# NANO100BN_v1 register map
File version: 1.0
Registers are 32-bit, read-write, reset 0x0 unless marked. A register's access mark holds for its fields unless they carry their own. Offsets are from the block's base; [hi:lo] are bit positions; {n}, {i} and the like mark numbered series; 'fields as' and 'values as' point back to an identical list.

## DAC — DAC Register Map
Base 0x400A0000
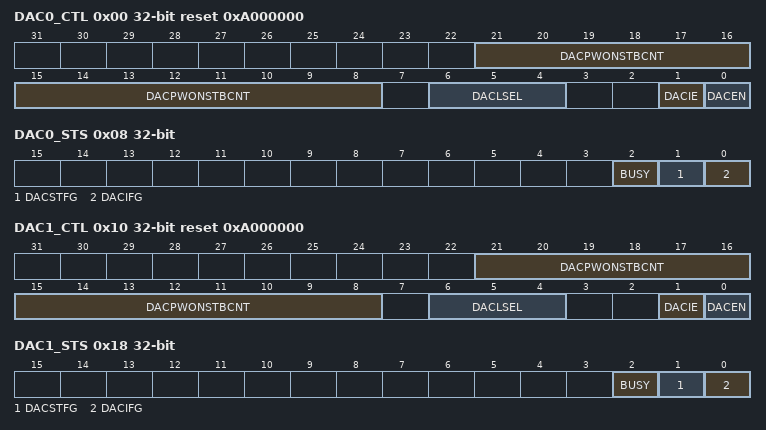
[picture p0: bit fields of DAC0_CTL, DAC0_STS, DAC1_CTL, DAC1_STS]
0x00 DAC0_CTL reset 0xA000000 — DAC0 Control Register
  [21:8] DACPWONSTBCNT — DACPWONSTBCNT. DAC need 6 us to be stable after DAC is power on from power down state. This fied controls a internal counter (in PCLK unit) to guarantee DAC stable time requirement.
  [6:4] DACLSEL — DAC Load Selection
  [1] DACIE — DAC Interrupt Enable
    0=Disabled; 1=Enabled
  [0] DACEN — DAC Enable. Note: When DAC is powered on, DAC will automatically start conversion after waiting for DACPWONSTBCNT+1 PCLK cycle.
    0=Power down DAC; 1=Power on DAC
0x04 DAC0_DATA
  [11:0] DACData
0x08 DAC0_STS — DAC0 Status Register
  [2] BUSY — BUSY bit
    0=DAC is not busy; 1=DAC is busy
  [1] DACSTFG — DAC start flag. Note: this bit is read only.
    0=DAC is not start yet; 1=DAC has been started
  [0] DACIFG — DAC Interrupt flag. Note: This bit is read only.
    0=No interrupt pending; 1=Interrupt pending
0x10 DAC1_CTL reset 0xA000000 — DAC1 Control Register
  fields as DAC0_CTL
0x14 DAC1_DATA
  [11:0] DACData
0x18 DAC1_STS — DAC1 Status Register
  fields as DAC0_STS
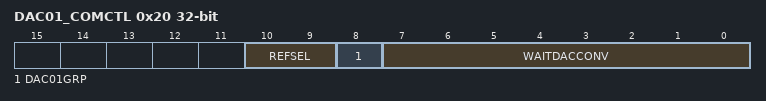
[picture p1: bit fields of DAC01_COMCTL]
0x20 DAC01_COMCTL — DAC01 Common Control Register
  [10:9] REFSEL — Reference Voltage Selection
  [8] DAC01GRP — Group DAC0 and DAC1.
    0=Not grouped; 1=Grouped
  [7:0] WAITDACCONV — Wait DAC Conversion Complete. The DAC needs at least 2 us to settle down every time when each data deliver to DAC, which means user cannot update each DACx_data register faster than 2 us; otherwise data will lost. Setting this register can adjust the time interval in PCLK unit between each DACx_data into DAC in order to meet the 2 us requirement.

## DMA_GCR — DMA Register Map
Base 0x50008F00
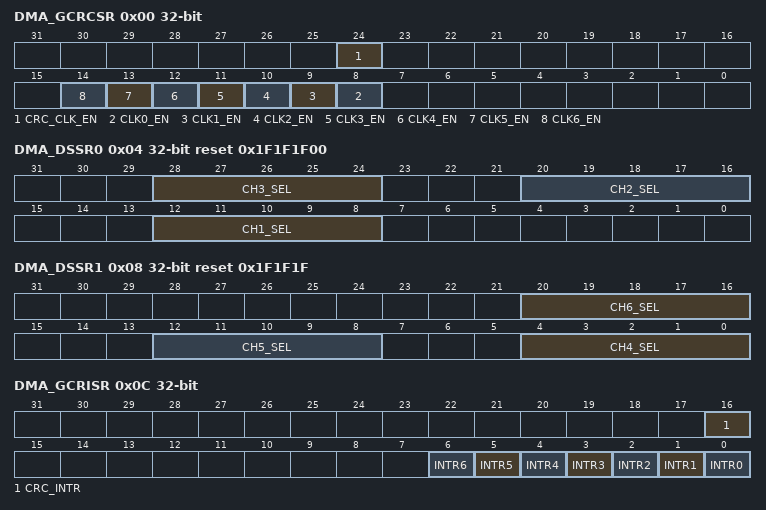
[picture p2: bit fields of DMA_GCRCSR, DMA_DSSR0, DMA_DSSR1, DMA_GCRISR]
0x00 DMA_GCRCSR — DMA Global Control and Status Register
  [all] fields
    0=Disabled; 1=Enabled
  [24] CRC_CLK_EN — CRC Controller Clock Enable Control
  [n+8] CLK{n}_EN (n=0..6) — DMA Controller Channel {n} Clock Enable Control
0x04 DMA_DSSR0 reset 0x1F1F1F00 — DMA Service Selection Control Register 0
  [28:24] CH3_SEL — Channel 3 Selection. This filed defines which peripheral is connected to PDMA channel 3. Software can configure the peripheral setting by CH3_SEL. The channel configuration is the same as CH1_SEL field. Please refer to the explanation of CH1_SEL.
  [20:16] CH2_SEL — Channel 2 Selection. This filed defines which peripheral is connected to PDMA channel 2. Software can configure the peripheral setting by CH2_SEL. The channel configuration is the same as CH1_SEL field. Please refer to the explanation of CH1_SEL.
  [12:8] CH1_SEL — Channel 1 Selection
0x08 DMA_DSSR1 reset 0x1F1F1F — DMA Service Selection Control Register 1
  [20:16] CH6_SEL — Channel 6 Selection. This filed defines which peripheral is connected to PDMA channel 6. Software can configure the peripheral setting by CH6_SEL. The channel configuration is the same as CH4_SEL field. Please refer to the explanation of CH4_SEL.
  [12:8] CH5_SEL — Channel 5 Selection. This filed defines which peripheral is connected to PDMA channel 5. Software can configure the peripheral setting by CH5_SEL. The channel configuration is the same as CH4_SEL field. Please refer to the explanation of CH4_SEL.
  [4:0] CH4_SEL — Channel 4 Selection
0x0C DMA_GCRISR ro — DMA Global Interrupt Status Register
  [16] CRC_INTR — Interrupt Pin Status of CRC Controller. This bit is the Interrupt status of CRC controller. Note: This bit is read only
  [6] INTR6 — Interrupt Pin Status Of Channel 6 (Read Only). This bit is the Interrupt pin status of DMA channel4. Note: This bit is read only
  [5] INTR5 — Interrupt Pin Status Of Channel 5 (Read Only). This bit is the Interrupt pin status of DMA channel4. Note: This bit is read only
  [n] INTR{n} (n=0..4) — Interrupt Pin Status Of Channel {n} (Read Only). This bit is the Interrupt pin status of DMA channel{n}. Note: This bit is read only
